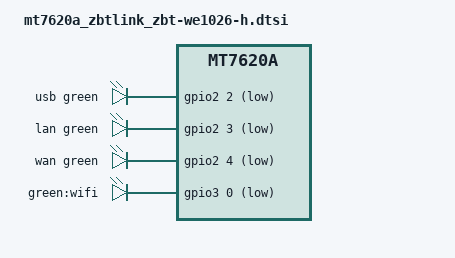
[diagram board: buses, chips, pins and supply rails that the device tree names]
// SPDX-License-Identifier: GPL-2.0-or-later OR MIT

#include <dt-bindings/leds/common.h>

#include "mt7620a_zbtlink_zbt-we1026.dtsi"

/ {
	compatible = "zbtlink,zbt-we1026-h", "zbtlink,zbt-we1026",
		"ralink,mt7620a-soc";

	leds {
		compatible = "gpio-leds";

		usb {
			function = LED_FUNCTION_USB;
			color = <LED_COLOR_ID_GREEN>;
			gpios = <&gpio2 2 GPIO_ACTIVE_LOW>;
		};

		lan {
			function = LED_FUNCTION_LAN;
			color = <LED_COLOR_ID_GREEN>;
			gpios = <&gpio2 3 GPIO_ACTIVE_LOW>;
		};

		wan {
			function = LED_FUNCTION_WAN;
			color = <LED_COLOR_ID_GREEN>;
			gpios = <&gpio2 4 GPIO_ACTIVE_LOW>;
		};

		wifi {
			label = "green:wifi";
			gpios = <&gpio3 0 GPIO_ACTIVE_LOW>;
		};
	};
};
